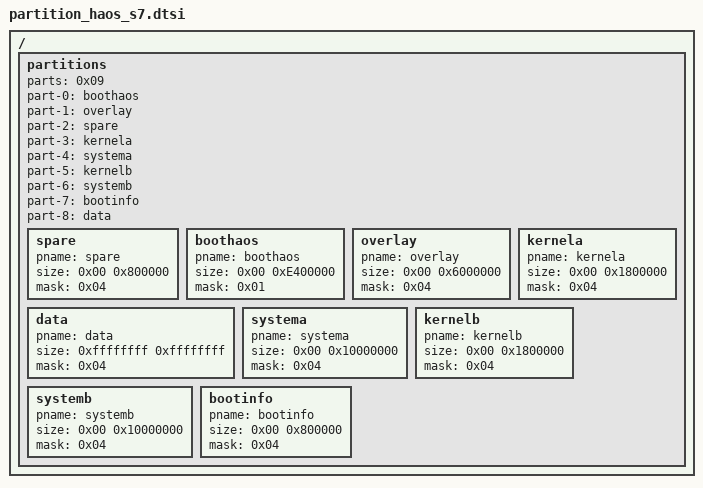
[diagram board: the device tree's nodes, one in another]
/*
 * HAOS layout for s7 boards (j310).
 */
/ {
	partitions: partitions {
		parts = <0x09>;
		part-0 = <&boothaos>;
		part-1 = <&overlay>;
		part-2 = <&spare>;
		part-3 = <&kernela>;
		part-4 = <&systema>;
		part-5 = <&kernelb>;
		part-6 = <&systemb>;
		part-7 = <&bootinfo>;
		part-8 = <&data>;

		spare: spare {
			pname = "spare";
			size = <0x00 0x800000>;
			mask = <0x04>;
		};
		boothaos: boothaos {
			pname = "boothaos";
			size = <0x00 0xE400000>;
			mask = <0x01>;
		};

		overlay: overlay {
			pname = "overlay";
			size = <0x00 0x6000000>;
			mask = <0x04>;
		};

		data: data {
			pname = "data";
			size = <0xffffffff 0xffffffff>;
			mask = <0x04>;
		};

		kernela: kernela {
			pname = "kernela";
			size = <0x00 0x1800000>;
			mask = <0x04>;
		};

		systema: systema {
			pname = "systema";
			size = <0x00 0x10000000>;
			mask = <0x04>;
		};

		kernelb: kernelb {
			pname = "kernelb";
			size = <0x00 0x1800000>;
			mask = <0x04>;
		};

		systemb: systemb {
			pname = "systemb";
			size = <0x00 0x10000000>;
			mask = <0x04>;
		};

		bootinfo: bootinfo {
			pname = "bootinfo";
			size = <0x00 0x800000>;
			mask = <0x04>;
		};
	};
};
